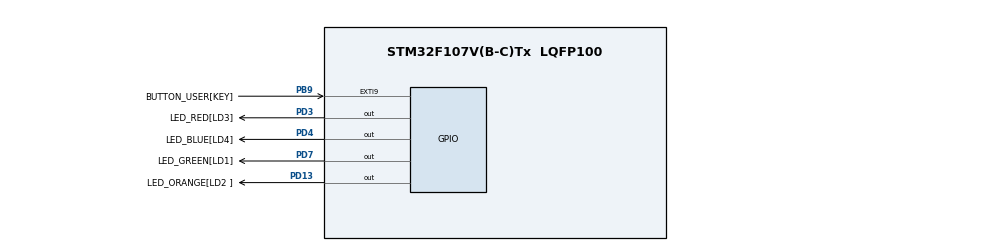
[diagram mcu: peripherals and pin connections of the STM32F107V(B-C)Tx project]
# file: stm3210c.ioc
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FREERTOS.HEAP_NUMBER=1
FREERTOS.Tasks01=defaultTask,0,128,StartDefaultTask,Default,NULL,Dynamic,NULL,NULL
FREERTOS.Timers01=myTimer01,Callback01,osTimerPeriodic,Default,NULL,Dynamic,NULL
FREERTOS.configUSE_COUNTING_SEMAPHORES=0
FREERTOS.configUSE_MUTEXES=0
FREERTOS.configUSE_TIMERS=1
FREERTOS.configUSE_TRACE_FACILITY=0
Mcu.Family=STM32F1
Mcu.Name=STM32F107V(B-C)Tx
Mcu.Package=LQFP100
NVIC.EXTI9_5_IRQn=true\:5\:0\:false\:false\:true\:true\:true
NVIC.PriorityGroup=NVIC_PRIORITYGROUP_4
NVIC.TIM7_IRQn=true\:0\:0\:false\:false\:true\:false\:false
NVIC.TimeBase=TIM7_IRQn
NVIC.TimeBaseIP=TIM7
PA13.Mode=Trace_Synchro_4bits_SW
PA13.Signal=SYS_JTMS-SWDIO
PA14.Mode=Trace_Synchro_4bits_SW
PA14.Signal=SYS_JTCK-SWCLK
PB9.GPIO_Label=BUTTON_USER[KEY]
PB9.GPIO_ModeDefaultEXTI=GPIO_MODE_IT_FALLING
PB9.GPIO_PuPd=GPIO_NOPULL
PB9.Signal=GPXTI9
PD13.GPIO_Label=LED_ORANGE[LD2 ]
PD13.GPIO_ModeDefaultOutputPP=GPIO_MODE_OUTPUT_PP
PD13.GPIO_Speed=GPIO_SPEED_FREQ_LOW
PD13.Signal=GPIO_Output
PD3.GPIO_Label=LED_RED[LD3]
PD3.GPIO_ModeDefaultOutputPP=GPIO_MODE_OUTPUT_PP
PD3.GPIO_Speed=GPIO_SPEED_FREQ_LOW
PD3.Signal=GPIO_Output
PD4.GPIO_Label=LED_BLUE[LD4]
PD4.GPIO_ModeDefaultOutputPP=GPIO_MODE_OUTPUT_PP
PD4.GPIO_Speed=GPIO_SPEED_FREQ_LOW
PD4.Signal=GPIO_Output
PD7.GPIO_Label=LED_GREEN[LD1]
PD7.GPIO_ModeDefaultOutputPP=GPIO_MODE_OUTPUT_PP
PD7.GPIO_Speed=GPIO_SPEED_FREQ_LOW
PD7.Signal=GPIO_Output
PE2.Mode=Trace_Synchro_4bits_SW
PE2.Signal=SYS_TRACECLK
PE3.Mode=Trace_Synchro_4bits_SW
PE3.Signal=SYS_TRACED0
PE4.Mode=Trace_Synchro_4bits_SW
PE4.Signal=SYS_TRACED1
PE5.Mode=Trace_Synchro_4bits_SW
PE5.Signal=SYS_TRACED2
PE6.Mode=Trace_Synchro_4bits_SW
PE6.Signal=SYS_TRACED3
ProjectManager.HeapSize=0x200
ProjectManager.StackSize=0x400
ProjectManager.TargetToolchain=MDK-ARM V5
RCC.DATA_CACHE_ENABLE=0
RCC.INSTRUCTION_CACHE_ENABLE=0
RCC.PREFETCH_ENABLE=0
RCC.USBFreq_Value=10666666.666666666
VP_FREERTOS_VS_ENABLE.Mode=Enabled
VP_SYS_VS_tim7.Mode=TIM7
board=stm3210c

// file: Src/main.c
/**
  ******************************************************************************
  * @file           : main.c
  * @brief          : Main program body
  ******************************************************************************
  * This notice applies to any and all portions of this file
  * that are not between comment pairs USER CODE BEGIN and
  * USER CODE END. Other portions of this file, whether
  * inserted by the user or by software development tools
  * are owned by their respective copyright owners.
  *
  * Copyright (c) 2018 STMicroelectronics International N.V.
  * All rights reserved.
  *
  * Redistribution and use in source and binary forms, with or without
  * modification, are permitted, provided that the following conditions are met:
  *
  * 1. Redistribution of source code must retain the above copyright notice,
  *    this list of conditions and the following disclaimer.
  * 2. Redistributions in binary form must reproduce the above copyright notice,
  *    this list of conditions and the following disclaimer in the documentation
  *    and/or other materials provided with the distribution.
  * 3. Neither the name of STMicroelectronics nor the names of other
  *    contributors to this software may be used to endorse or promote products
  *    derived from this software without specific written permission.
  * 4. This software, including modifications and/or derivative works of this
  *    software, must execute solely and exclusively on microcontroller or
  *    microprocessor devices manufactured by or for STMicroelectronics.
  * 5. Redistribution and use of this software other than as permitted under
  *    this license is void and will automatically terminate your rights under
  *    this license.
  *
  * THIS SOFTWARE IS PROVIDED BY STMICROELECTRONICS AND CONTRIBUTORS "AS IS"
  * AND ANY EXPRESS, IMPLIED OR STATUTORY WARRANTIES, INCLUDING, BUT NOT
  * LIMITED TO, THE IMPLIED WARRANTIES OF MERCHANTABILITY, FITNESS FOR A
  * PARTICULAR PURPOSE AND NON-INFRINGEMENT OF THIRD PARTY INTELLECTUAL PROPERTY
  * RIGHTS ARE DISCLAIMED TO THE FULLEST EXTENT PERMITTED BY LAW. IN NO EVENT
  * SHALL STMICROELECTRONICS OR CONTRIBUTORS BE LIABLE FOR ANY DIRECT, INDIRECT,
  * INCIDENTAL, SPECIAL, EXEMPLARY, OR CONSEQUENTIAL DAMAGES (INCLUDING, BUT NOT
  * LIMITED TO, PROCUREMENT OF SUBSTITUTE GOODS OR SERVICES; LOSS OF USE, DATA,
  * OR PROFITS; OR BUSINESS INTERRUPTION) HOWEVER CAUSED AND ON ANY THEORY OF
  * LIABILITY, WHETHER IN CONTRACT, STRICT LIABILITY, OR TORT (INCLUDING
  * NEGLIGENCE OR OTHERWISE) ARISING IN ANY WAY OUT OF THE USE OF THIS SOFTWARE,
  * EVEN IF ADVISED OF THE POSSIBILITY OF SUCH DAMAGE.
  *
  ******************************************************************************
  */
#include "main.h"
#include "stm32f1xx_hal.h"
#include "cmsis_os.h"

/* USER CODE BEGIN Includes */
#include "led.h"
/* USER CODE END Includes */

osThreadId defaultTaskHandle;
osTimerId myTimer01Handle;

/* USER CODE BEGIN PV */
/* Private variables ---------------------------------------------------------*/

/* USER CODE END PV */

void SystemClock_Config(void);
static void MX_GPIO_Init(void);
void StartDefaultTask(void const * argument);
void Callback01(void const * argument);

/* USER CODE BEGIN PFP */
/* Private function prototypes -----------------------------------------------*/

/* USER CODE END PFP */

/* USER CODE BEGIN 0 */

  uint16_t ProducerValue = 0;
	uint16_t ConsumerValue = 0;

/* USER CODE END 0 */

int main(void)
{

  /* MCU Configuration----------------------------------------------------------*/

  /* Reset of all peripherals, Initializes the Flash interface and the Systick. */
  HAL_Init();

  /* Configure the system clock */
  SystemClock_Config();

  /* Initialize all configured peripherals */
  MX_GPIO_Init();

  /* Create the timer(s) */
  /* definition and creation of myTimer01 */
  osTimerDef(myTimer01, Callback01);
  myTimer01Handle = osTimerCreate(osTimer(myTimer01), osTimerPeriodic, NULL);

  /* USER CODE BEGIN RTOS_TIMERS */
  /* start timers, add new ones, ... */
	osTimerStart(myTimer01Handle, 100);
  /* USER CODE END RTOS_TIMERS */

  /* Create the thread(s) */
  /* definition and creation of defaultTask */
  osThreadDef(defaultTask, StartDefaultTask, osPriorityNormal, 0, 128);
  defaultTaskHandle = osThreadCreate(osThread(defaultTask), NULL);

  /* Start scheduler */
  osKernelStart();

  /* We should never get here as control is now taken by the scheduler */

  /* Infinite loop */
  while (1)
  {

  }

}

void SystemClock_Config(void)
{

  RCC_OscInitTypeDef RCC_OscInitStruct;
  RCC_ClkInitTypeDef RCC_ClkInitStruct;

    /**Initializes the CPU, AHB and APB busses clocks
    */
  RCC_OscInitStruct.OscillatorType = RCC_OSCILLATORTYPE_HSI;
  RCC_OscInitStruct.HSIState = RCC_HSI_ON;
  RCC_OscInitStruct.HSICalibrationValue = 16;
  RCC_OscInitStruct.PLL.PLLState = RCC_PLL_NONE;
  RCC_OscInitStruct.PLL2.PLL2State = RCC_PLL_NONE;
  if (HAL_RCC_OscConfig(&RCC_OscInitStruct) != HAL_OK)
  {
    _Error_Handler(__FILE__, __LINE__);
  }

    /**Initializes the CPU, AHB and APB busses clocks
    */
  RCC_ClkInitStruct.ClockType = RCC_CLOCKTYPE_HCLK|RCC_CLOCKTYPE_SYSCLK
                              |RCC_CLOCKTYPE_PCLK1|RCC_CLOCKTYPE_PCLK2;
  RCC_ClkInitStruct.SYSCLKSource = RCC_SYSCLKSOURCE_HSI;
  RCC_ClkInitStruct.AHBCLKDivider = RCC_SYSCLK_DIV1;
  RCC_ClkInitStruct.APB1CLKDivider = RCC_HCLK_DIV1;
  RCC_ClkInitStruct.APB2CLKDivider = RCC_HCLK_DIV1;

  if (HAL_RCC_ClockConfig(&RCC_ClkInitStruct, FLASH_LATENCY_0) != HAL_OK)
  {
    _Error_Handler(__FILE__, __LINE__);
  }

    /**Configure the Systick interrupt time
    */
  HAL_SYSTICK_Config(HAL_RCC_GetHCLKFreq()/1000);

    /**Configure the Systick
    */
  HAL_SYSTICK_CLKSourceConfig(SYSTICK_CLKSOURCE_HCLK);

    /**Configure the Systick interrupt time
    */
  __HAL_RCC_PLLI2S_ENABLE();

  /* SysTick_IRQn interrupt configuration */
  HAL_NVIC_SetPriority(SysTick_IRQn, 15, 0);
}

/** Configure pins as
        * Analog
        * Input
        * Output
        * EVENT_OUT
        * EXTI
*/
static void MX_GPIO_Init(void)
{

  GPIO_InitTypeDef GPIO_InitStruct;

  /* GPIO Ports Clock Enable */
  __HAL_RCC_GPIOE_CLK_ENABLE();
  __HAL_RCC_GPIOD_CLK_ENABLE();
  __HAL_RCC_GPIOA_CLK_ENABLE();
  __HAL_RCC_GPIOB_CLK_ENABLE();

  /*Configure GPIO pin Output Level */
  HAL_GPIO_WritePin(GPIOD, LED_ORANGE_Pin|LED_RED_Pin|LED_BLUE_Pin|LED_GREEN_Pin, GPIO_PIN_RESET);

  /*Configure GPIO pins : LED_ORANGE_Pin LED_RED_Pin LED_BLUE_Pin LED_GREEN_Pin */
  GPIO_InitStruct.Pin = LED_ORANGE_Pin|LED_RED_Pin|LED_BLUE_Pin|LED_GREEN_Pin;
  GPIO_InitStruct.Mode = GPIO_MODE_OUTPUT_PP;
  GPIO_InitStruct.Speed = GPIO_SPEED_FREQ_LOW;
  HAL_GPIO_Init(GPIOD, &GPIO_InitStruct);

  /*Configure GPIO pin : BUTTON_USER_Pin */
  GPIO_InitStruct.Pin = BUTTON_USER_Pin;
  GPIO_InitStruct.Mode = GPIO_MODE_IT_FALLING;
  GPIO_InitStruct.Pull = GPIO_NOPULL;
  HAL_GPIO_Init(BUTTON_USER_GPIO_Port, &GPIO_InitStruct);

  /* EXTI interrupt init*/
  HAL_NVIC_SetPriority(EXTI9_5_IRQn, 5, 0);
  HAL_NVIC_EnableIRQ(EXTI9_5_IRQn);

}

/* USER CODE BEGIN 4 */

void HAL_GPIO_EXTI_Callback(uint16_t GPIO_Pin)
{
	if(GPIO_Pin == GPIO_PIN_9)
	{
		HAL_Delay(1);
		if(HAL_GPIO_ReadPin(BUTTON_USER_GPIO_Port,BUTTON_USER_Pin)== GPIO_PIN_RESET)
		{
			//do something
		}
	}
}

/* USER CODE END 4 */

/* StartDefaultTask function */
void StartDefaultTask(void const * argument)
{

  /* USER CODE BEGIN 5 */

	for(;;)
	{
		BSP_LED_Toggle(LED_BLUE);
		osDelay(100);
	}

  /* USER CODE END 5 */
}

/* Callback01 function */
void Callback01(void const * argument)
{
  /* USER CODE BEGIN Callback01 */
  BSP_LED_Toggle(LED_RED);
  /* USER CODE END Callback01 */
}

void HAL_TIM_PeriodElapsedCallback(TIM_HandleTypeDef *htim)
{
  if (htim->Instance == TIM7) {
    HAL_IncTick();
  }
}

void _Error_Handler(char *file, int line)
{
  while(1)
  {
  }
}

/************************ (C) COPYRIGHT STMicroelectronics *****END OF FILE****/
